# PIC32MM0128GPM036 register map
Vendor: Microchip
Registers are 32-bit, read-write, reset 0x0 unless marked. A register's access mark holds for its fields unless they carry their own. Addresses are absolute, and some are shared; only a register's first bit layout is shown; [hi:lo] are bit positions; 'fields as' and 'values as' point back to an identical list.

## RTCC
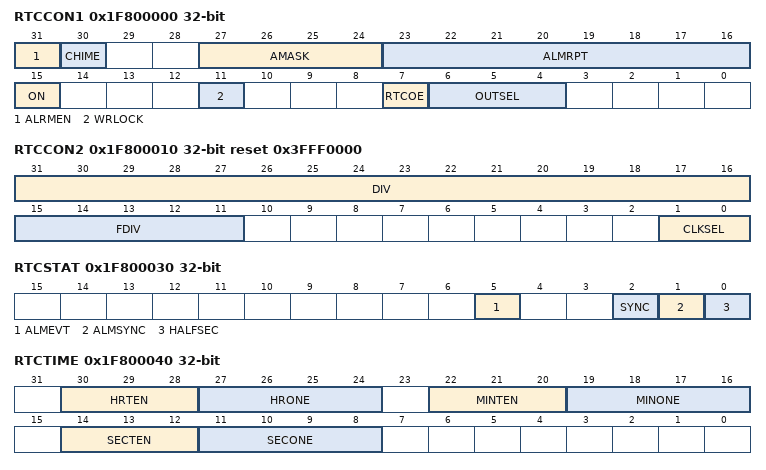
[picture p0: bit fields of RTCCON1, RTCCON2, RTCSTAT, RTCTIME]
0x1F800000 RTCCON1
  [31] ALRMEN, [30] CHIME, [27:24] AMASK, [23:16] ALMRPT, [15] ON, [11] WRLOCK, [7] RTCOE, [6:4] OUTSEL
0x1F800010 RTCCON2 reset 0x3FFF0000
  [31:16] DIV, [15:11] FDIV, [1:0] CLKSEL
0x1F800030 RTCSTAT
  [5] ALMEVT — (can only be cleared)
  [2] SYNC ro
  [1] ALMSYNC ro
  [0] HALFSEC ro
0x1F800040 RTCTIME
  [30:28] HRTEN, [27:24] HRONE, [22:20] MINTEN, [19:16] MINONE, [14:12] SECTEN, [11:8] SECONE
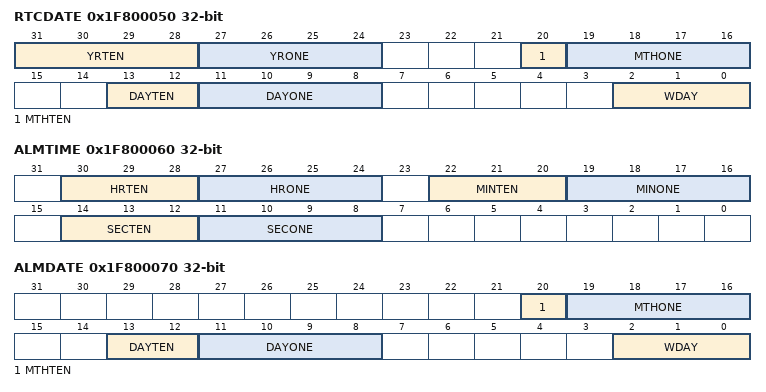
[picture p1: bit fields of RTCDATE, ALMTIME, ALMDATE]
0x1F800050 RTCDATE
  [31:28] YRTEN, [27:24] YRONE, [20] MTHTEN, [19:16] MTHONE, [13:12] DAYTEN, [11:8] DAYONE, [2:0] WDAY
0x1F800060 ALMTIME
  fields as RTCTIME
0x1F800070 ALMDATE
  [20] MTHTEN, [19:16] MTHONE, [13:12] DAYTEN, [11:8] DAYONE, [2:0] WDAY

## CCP1
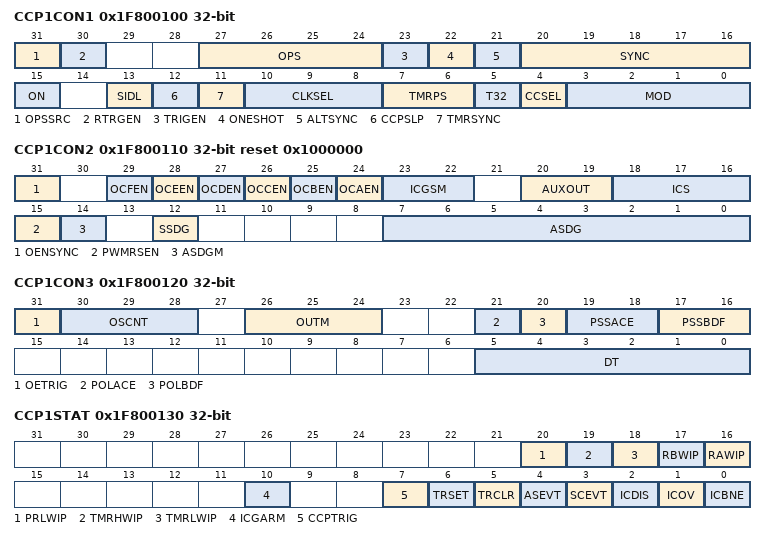
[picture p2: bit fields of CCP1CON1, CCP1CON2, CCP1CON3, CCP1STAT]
0x1F800100 CCP1CON1
  [31] OPSSRC, [30] RTRGEN, [27:24] OPS, [23] TRIGEN, [22] ONESHOT, [21] ALTSYNC, [20:16] SYNC, [15] ON, [13] SIDL, [12] CCPSLP, [11] TMRSYNC, [10:8] CLKSEL, [7:6] TMRPS, [5] T32, [4] CCSEL, [3:0] MOD
0x1F800110 CCP1CON2 reset 0x1000000
  [31] OENSYNC, [29] OCFEN, [28] OCEEN, [27] OCDEN, [26] OCCEN, [25] OCBEN, [24] OCAEN, [23:22] ICGSM, [20:19] AUXOUT, [18:16] ICS, [15] PWMRSEN, [14] ASDGM, [12] SSDG, [7:0] ASDG
0x1F800120 CCP1CON3
  [31] OETRIG, [30:28] OSCNT, [26:24] OUTM, [21] POLACE, [20] POLBDF, [19:18] PSSACE, [17:16] PSSBDF, [5:0] DT
0x1F800130 CCP1STAT
  [20] PRLWIP
  [19] TMRHWIP
  [18] TMRLWIP
  [17] RBWIP
  [16] RAWIP
  [10] ICGARM
  [7] CCPTRIG ro
  [6] TRSET
  [5] TRCLR
  [4] ASEVT — (can only be cleared)
  [3] SCEVT — (can only be cleared)
  [2] ICDIS ro
  [1] ICOV — (can only be cleared)
  [0] ICBNE ro
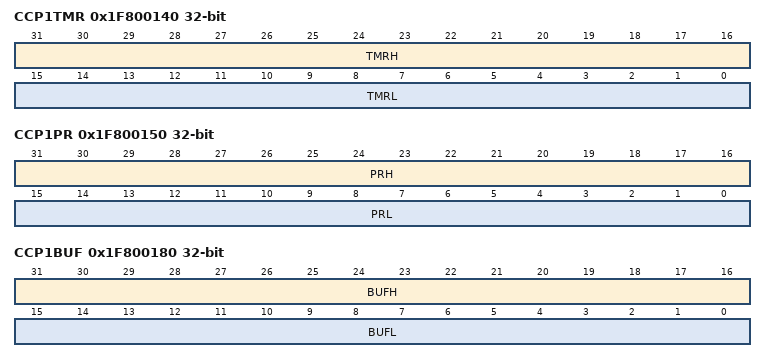
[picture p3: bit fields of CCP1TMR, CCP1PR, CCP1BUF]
0x1F800140 CCP1TMR
  [31:16] TMRH, [15:0] TMRL
0x1F800150 CCP1PR
  [31:16] PRH, [15:0] PRL
0x1F800160 CCP1RA
  [15:0] CMPA
0x1F800170 CCP1RB
  [15:0] CMPB
0x1F800180 CCP1BUF
  [31:16] BUFH, [15:0] BUFL

## CCP2
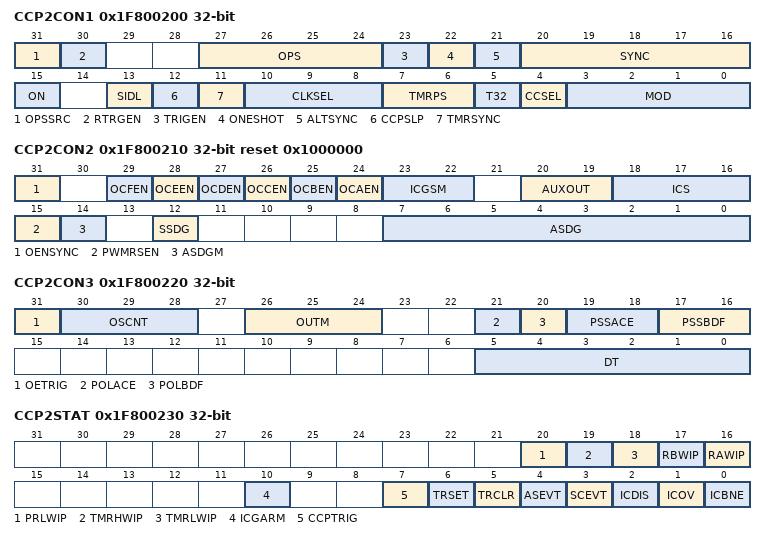
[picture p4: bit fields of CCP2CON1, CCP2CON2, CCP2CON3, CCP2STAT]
0x1F800200 CCP2CON1
  [31] OPSSRC, [30] RTRGEN, [27:24] OPS, [23] TRIGEN, [22] ONESHOT, [21] ALTSYNC, [20:16] SYNC, [15] ON, [13] SIDL, [12] CCPSLP, [11] TMRSYNC, [10:8] CLKSEL, [7:6] TMRPS, [5] T32, [4] CCSEL, [3:0] MOD
0x1F800210 CCP2CON2 reset 0x1000000
  [31] OENSYNC, [29] OCFEN, [28] OCEEN, [27] OCDEN, [26] OCCEN, [25] OCBEN, [24] OCAEN, [23:22] ICGSM, [20:19] AUXOUT, [18:16] ICS, [15] PWMRSEN, [14] ASDGM, [12] SSDG, [7:0] ASDG
0x1F800220 CCP2CON3
  [31] OETRIG, [30:28] OSCNT, [26:24] OUTM, [21] POLACE, [20] POLBDF, [19:18] PSSACE, [17:16] PSSBDF, [5:0] DT
0x1F800230 CCP2STAT
  [20] PRLWIP
  [19] TMRHWIP
  [18] TMRLWIP
  [17] RBWIP
  [16] RAWIP
  [10] ICGARM
  [7] CCPTRIG ro
  [6] TRSET
  [5] TRCLR
  [4] ASEVT — (can only be cleared)
  [3] SCEVT — (can only be cleared)
  [2] ICDIS ro
  [1] ICOV — (can only be cleared)
  [0] ICBNE ro
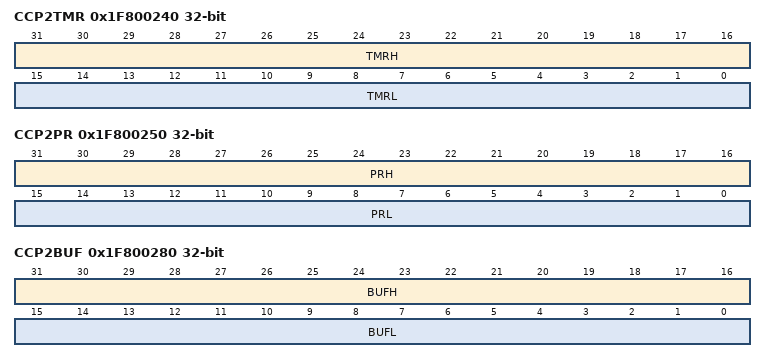
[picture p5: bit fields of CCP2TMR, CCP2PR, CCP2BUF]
0x1F800240 CCP2TMR
  [31:16] TMRH, [15:0] TMRL
0x1F800250 CCP2PR
  [31:16] PRH, [15:0] PRL
0x1F800260 CCP2RA
  [15:0] CMPA
0x1F800270 CCP2RB
  [15:0] CMPB
0x1F800280 CCP2BUF
  [31:16] BUFH, [15:0] BUFL

## CCP3
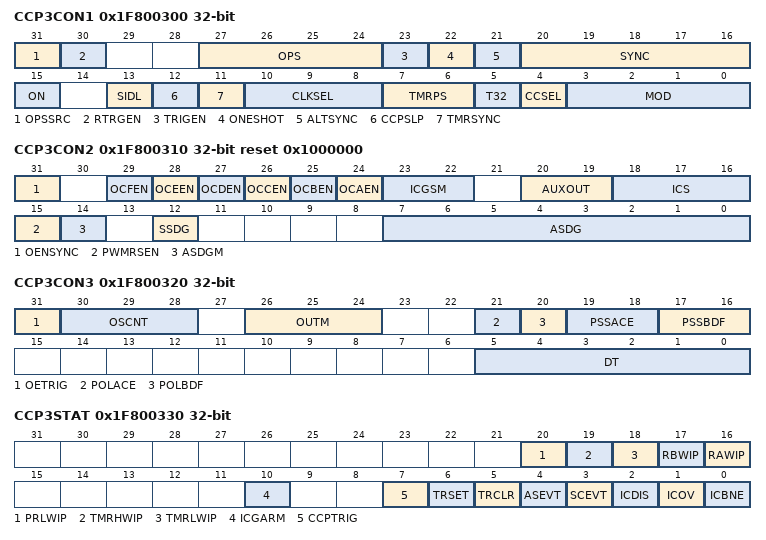
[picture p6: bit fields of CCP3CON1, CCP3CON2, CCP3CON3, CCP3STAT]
0x1F800300 CCP3CON1
  [31] OPSSRC, [30] RTRGEN, [27:24] OPS, [23] TRIGEN, [22] ONESHOT, [21] ALTSYNC, [20:16] SYNC, [15] ON, [13] SIDL, [12] CCPSLP, [11] TMRSYNC, [10:8] CLKSEL, [7:6] TMRPS, [5] T32, [4] CCSEL, [3:0] MOD
0x1F800310 CCP3CON2 reset 0x1000000
  [31] OENSYNC, [29] OCFEN, [28] OCEEN, [27] OCDEN, [26] OCCEN, [25] OCBEN, [24] OCAEN, [23:22] ICGSM, [20:19] AUXOUT, [18:16] ICS, [15] PWMRSEN, [14] ASDGM, [12] SSDG, [7:0] ASDG
0x1F800320 CCP3CON3
  [31] OETRIG, [30:28] OSCNT, [26:24] OUTM, [21] POLACE, [20] POLBDF, [19:18] PSSACE, [17:16] PSSBDF, [5:0] DT
0x1F800330 CCP3STAT
  [20] PRLWIP
  [19] TMRHWIP
  [18] TMRLWIP
  [17] RBWIP
  [16] RAWIP
  [10] ICGARM
  [7] CCPTRIG ro
  [6] TRSET
  [5] TRCLR
  [4] ASEVT — (can only be cleared)
  [3] SCEVT — (can only be cleared)
  [2] ICDIS ro
  [1] ICOV — (can only be cleared)
  [0] ICBNE ro
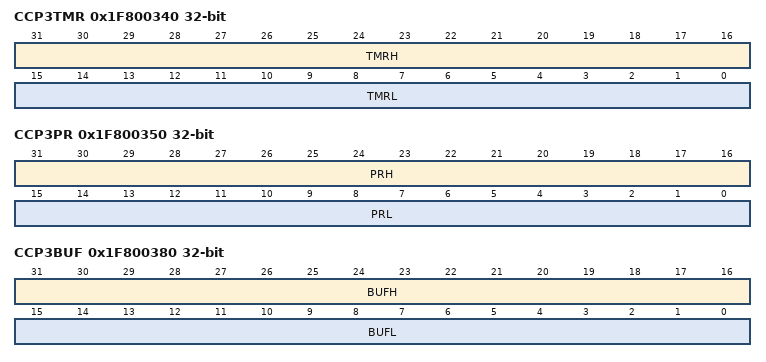
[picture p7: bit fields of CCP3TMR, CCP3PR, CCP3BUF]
0x1F800340 CCP3TMR
  [31:16] TMRH, [15:0] TMRL
0x1F800350 CCP3PR
  [31:16] PRH, [15:0] PRL
0x1F800360 CCP3RA
  [15:0] CMPA
0x1F800370 CCP3RB
  [15:0] CMPB
0x1F800380 CCP3BUF
  [31:16] BUFH, [15:0] BUFL
